# PY32F002Bxx register map
Vendor: Puya; Series: PY32F0; File version: 1.0.0
CPU: CM0+ r0p1, little endian, no MPU, no FPU, 4 interrupt priority bits
Registers are 32-bit, read-write, reset 0x0 unless marked. A register's access mark holds for its fields unless they carry their own. Offsets are from the block's base; [hi:lo] are bit positions; {n}, {i} and the like mark numbered series; 'fields as' and 'values as' point back to an identical list.

## IWDG — Independent watchdog
Base 0x40003000
0x00 KR wo — Key register (IWDG_KR)
  [15:0] KEY — Key value
    0x5555=Enable access to PR, RLR and WINR registers (0x5555); 0xAAAA=Reset the watchdog value (0xAAAA); 0xCCCC=Start the watchdog (0xCCCC)
0x04 PR — Prescaler register (IWDG_PR)
  [2:0] PR — Prescaler divider
    0=DivideBy4 (Divider /4); 1=DivideBy8 (Divider /8); 2=DivideBy16 (Divider /16); 3=DivideBy32 (Divider /32); 4=DivideBy64 (Divider /64); 5=DivideBy128 (Divider /128); 6=DivideBy256 (Divider /256); 7=DivideBy256bis (Divider /256)
0x08 RLR reset 0xFFF — Reload register (IWDG_RLR)
  [11:0] RL — Watchdog counter reload value
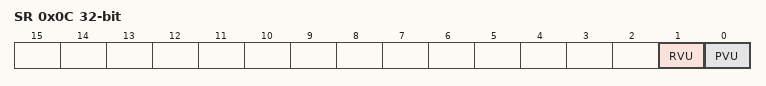
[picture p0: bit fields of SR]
0x0C SR ro — Status register (IWDG_SR)
  [1] RVU — Watchdog counter reload value update
    0=Idle (No update on-going); 1=Busy (Update on-going)
  [0] PVU — Watchdog prescaler value update
    0=Idle (No update on-going); 1=Busy (Update on-going)

## TIM14 — General purpose timer
Base 0x40002000
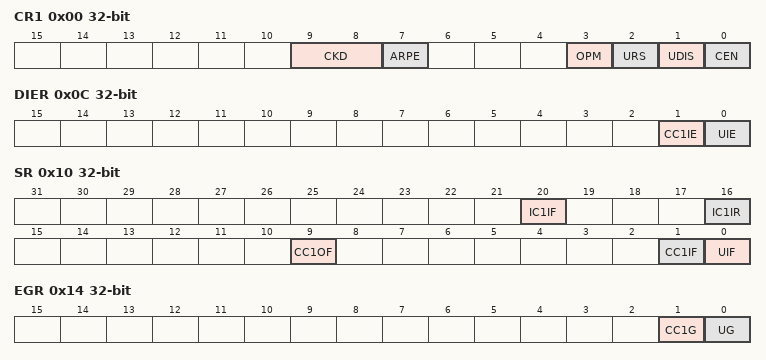
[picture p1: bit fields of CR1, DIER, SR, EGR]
0x00 CR1
  [9:8] CKD
  [7] ARPE
    0=Disabled (TIMx_APRR register is not buffered); 1=Enabled (TIMx_APRR register is buffered)
  [3] OPM
  [2] URS
    0=AnyEvent (Any of counter overflow/underflow, setting UG, or update through slave mode, generates an update interrupt or DMA request); 1=CounterOnly (Only counter overflow/underflow generates an update interrupt or DMA request)
  [1] UDIS
    0=Enabled (Update event enabled); 1=Disabled (Update event disabled)
  [0] CEN
    0=Disabled (Counter disabled); 1=Enabled (Counter enabled)
0x0C DIER
  [1] CC1IE, [0] UIE
0x10 SR (reset mask 0x1E5F)
  [20] IC1IF, [16] IC1IR, [9] CC1OF, [1] CC1IF, [0] UIF
0x14 EGR wo
  [1] CC1G — Capture/Compare 1 Generation
  [0] UG
    1=Trigger (Re-initializes the timer counter and generates an update of the registers.)
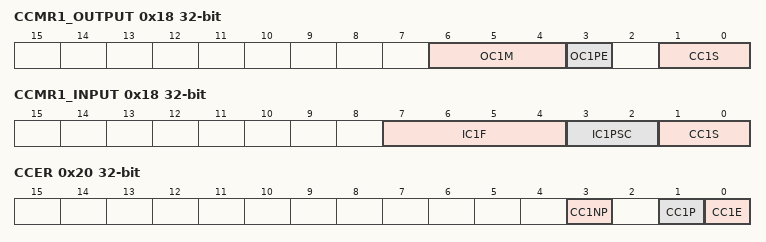
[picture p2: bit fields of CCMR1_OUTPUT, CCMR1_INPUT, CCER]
0x18 CCMR1_OUTPUT
  [6:4] OC1M, [3] OC1PE, [1:0] CC1S
0x18 CCMR1_INPUT (alternate view of CCMR1_OUTPUT)
  [7:4] IC1F, [3:2] IC1PSC, [1:0] CC1S
0x20 CCER (reset mask 0x3333)
  [3] CC1NP, [1] CC1P, [0] CC1E
0x24 CNT
  [15:0] CNT
0x28 PSC
  [15:0] PSC
0x2C ARR reset 0xFFFF
  [15:0] ARR
{0x30+4i} CCR{i} (i=1..1) — desc CCR{i}
  [15:0] CCR — desc CCR1
0x50 OR
  [1:0] TI1_RMP

## SYSCFG — System configuration controller
Base 0x40010000
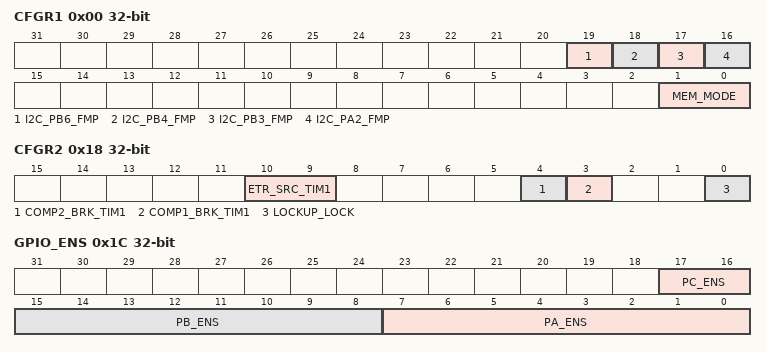
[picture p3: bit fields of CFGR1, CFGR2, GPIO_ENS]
0x00 CFGR1 — SYSCFG configuration register 1
  [19] I2C_PB6_FMP
    0=Standard (Pin operate in standard mode); 1=AnalogFilter (I2C FM+ mode enabled on pin)
  [18] I2C_PB4_FMP
    values as I2C_PB6_FMP
  [17] I2C_PB3_FMP
    values as I2C_PB6_FMP
  [16] I2C_PA2_FMP
    values as I2C_PB6_FMP
  [1:0] MEM_MODE — Memory mapping selection bits
    0=Main Flash memory mapped at 0x0000_0000; 1=System Flash memory mapped at 0x0000_0000; 2=MainFlash2 (Main Flash memory mapped at 0x0000_0000); 3=SRAM (Embedded SRAM mapped at 0x0000_0000)
0x18 CFGR2 — SYSCFG configuration register 2
  [10:9] ETR_SRC_TIM1 — TIM1 ETR source selection
    0=GPIO (TIM1_ETR is connected to GPIO); 1=COMP1 (TIM1_ETR is connected to COMP1); 2=COMP2 (TIM1_ETR is connected to COMP2); 3=ADC (TIM1_ETR is connected to ADC)
  [4] COMP2_BRK_TIM1 — COMP2 output connect to TIM1 Break input
    0=Disconnected (COMP? output not connect to TIM? Break input); 1=Connected (COMP? output connected to TIM? Break input)
  [3] COMP1_BRK_TIM1 — COMP1 output connect to TIM1 Break input
    values as COMP2_BRK_TIM1
  [0] LOCKUP_LOCK — Cortex-M0+ LOCKUP bit enable bit
    0=Disconnected (Cortex-M0+ LOCKUP output disconnected from TIM1/16/17 Break input); 1=Connected (Cortex-M0+ LOCKUP output connected to TIM1/16/17 Break input)
0x1C GPIO_ENS
  [17:16] PC_ENS, [15:8] PB_ENS range 0..63, [7:0] PA_ENS range 0..63

## CRC — CRC calculation unit
Base 0x40023000
0x00 DR reset 0xFFFFFFFF — Data register
  [31:0] DR — Data Register
0x04 IDR — Independent Data register
  [7:0] IDR
0x08 CR wo — Control register
  [0] RESET — Reset bit
    1=Resets the CRC calculation unit and sets the data register to 0xFFFF FFFF
